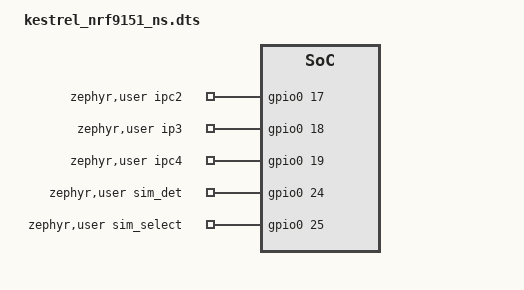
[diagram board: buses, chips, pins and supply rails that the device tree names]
/*
 * Copyright (c) 2024 Nordic Semiconductor
 * SPDX-License-Identifier: LicenseRef-Nordic-5-Clause
 */

/dts-v1/;
#include <nordic/nrf9151ns_laca.dtsi>
#include "kestrel_nrf9151_common.dts"

/ {
	chosen {
		zephyr,flash = &flash0;
		zephyr,sram = &sram0_ns_app;
		zephyr,code-partition = &slot0_ns_partition;

	};

	zephyr,user {
		ipc2-gpios = <&gpio0 17 0>;
		ip3-gpios = <&gpio0 18 0>;
		ipc4-gpios = <&gpio0 19 0>;
		sim_det-gpios = <&gpio0 24 0>;
		sim_select-gpios = <&gpio0 25 0>;
	};
};


&power {
	status = "okay";
};

&ipc {
	status = "okay";
};

&gpiote {
	status = "okay";
};



&systick {
	status = "disabled";
};
